# STM32WBA55 register map
File version: 1.0
CPU: CM33 r0p1, little endian, MPU, FPU, 4 interrupt priority bits
Registers are 32-bit, read-write, reset 0x0 unless marked. A register's access mark holds for its fields unless they carry their own. Offsets are from the block's base; [hi:lo] are bit positions; {n}, {i} and the like mark numbered series.

## ADC4 — ADC register block
Base 0x46021000
Same registers: SEC_ADC4 0x56021000
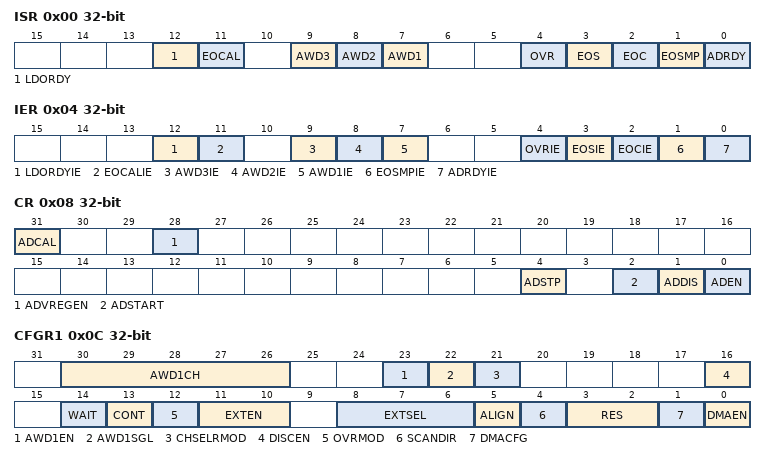
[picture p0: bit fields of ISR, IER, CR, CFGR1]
0x00 ISR — ADC interrupt and status register
  [12] LDORDY — LDO ready This bit is set by hardware. It indicates that the ADC internal LDO output is ready. It is cleared by software by writing 1 to it.
  [11] EOCAL — End of calibration flag This bit is set by hardware when calibration is complete. It is cleared by software writing 1 to it.
  [9] AWD3 — Analog watchdog 3 flag This bit is set by hardware when the converted voltage crosses the values programmed in ADC_AWD3TR and ADC_AWD3TR registers. It is cleared by software by writing 1 to it.
  [8] AWD2 — Analog watchdog 2 flag This bit is set by hardware when the converted voltage crosses the values programmed in ADC_AWD2TR and ADC_AWD2TR registers. It is cleared by software writing 1 to it.
  [7] AWD1 — Analog watchdog 1 flag This bit is set by hardware when the converted voltage crosses the values programmed in ADC_TR1 and ADC_HR1 registers. It is cleared by software by writing 1 to it.
  [4] OVR — ADC overrun This bit is set by hardware when an overrun occurs, meaning that a new conversion has complete while the EOC flag was already set. It is cleared by software writing 1 to it.
  [3] EOS — End of sequence flag This bit is set by hardware at the end of the conversion of a sequence of channels selected by the CHSEL bits. It is cleared by software writing 1 to it.
  [2] EOC — End of conversion flag This bit is set by hardware at the end of each conversion of a channel when a new data result is available in the ADC_DR register. It is cleared by software writing 1 to it or by reading the ADC_DR register.
  [1] EOSMP — End of sampling flag This bit is set by hardware during the conversion, at the end of the sampling phase.It is cleared by software by writing 1 to it.
  [0] ADRDY — ADC ready This bit is set by hardware after the ADC has been enabled (ADEN = 1) and when the ADC reaches a state where it is ready to accept conversion requests. It is cleared by software writing 1 to it.
0x04 IER — ADC interrupt enable register
  [12] LDORDYIE — LDO ready interrupt enable This bit is set and cleared by software. It is used to enable/disable the LDORDY interrupt. Note: The software is allowed to write this bit only when ADSTART bit is cleared to 0 by writing ADSTP to 1 (this ensure that no conversion is ongoing).
  [11] EOCALIE — End of calibration interrupt enable This bit is set and cleared by software to enable/disable the end of calibration interrupt. Note: The software is allowed to write this bit only when ADSTART bit is cleared to 0 by writing ADSTP to 1 (this ensures that no conversion is ongoing).
  [9] AWD3IE — Analog watchdog 3 interrupt enable This bit is set and cleared by software to enable/disable the analog watchdog interrupt. Note: The Software is allowed to write this bit only when ADSTART bit is cleared to 0 by writing ADSTP to 1 (this ensures that no conversion is ongoing).
  [8] AWD2IE — Analog watchdog 2 interrupt enable This bit is set and cleared by software to enable/disable the analog watchdog interrupt. Note: The Software is allowed to write this bit only when ADSTART bit is cleared to 0 by writing ADSTP to 1 (this ensures that no conversion is ongoing).
  [7] AWD1IE — Analog watchdog 1 interrupt enable This bit is set and cleared by software to enable/disable the analog watchdog interrupt. Note: The Software is allowed to write this bit only when ADSTART bit is cleared to 0 by writing ADSTP to 1 (this ensures that no conversion is ongoing).
  [4] OVRIE — Overrun interrupt enable This bit is set and cleared by software to enable/disable the overrun interrupt. Note: The software is allowed to write this bit only when ADSTART bit is cleared to 0 by writing ADSTP to 1 (this ensures that no conversion is ongoing).
  [3] EOSIE — End of conversion sequence interrupt enable This bit is set and cleared by software to enable/disable the end of sequence of conversions interrupt. Note: The software is allowed to write this bit only when ADSTART bit is cleared to 0 by writing ADSTP to 1 (this ensures that no conversion is ongoing).
  [2] EOCIE — End of conversion interrupt enable This bit is set and cleared by software to enable/disable the end of conversion interrupt. Note: The software is allowed to write this bit only when ADSTART bit is cleared to 0 by writing ADSTP to 1 (this ensures that no conversion is ongoing).
  [1] EOSMPIE — End of sampling flag interrupt enable This bit is set and cleared by software to enable/disable the end of the sampling phase interrupt. Note: The software is allowed to write this bit only when ADSTART bit is cleared to 0 by writing ADSTP to 1 (this ensures that no conversion is ongoing).
  [0] ADRDYIE — ADC ready interrupt enable This bit is set and cleared by software to enable/disable the ADC Ready interrupt. Note: The software is allowed to write this bit only when ADSTART bit is cleared to 0 by writing ADSTP to 1 (this ensures that no conversion is ongoing).
0x08 CR — ADC control register
  [31] ADCAL — ADC calibration This bit is set by software to start the calibration of the ADC. It is cleared by hardware after calibration is complete. Note: The software is allowed to set ADCAL only when the ADC is disabled (ADCAL = 0, ADSTART = 0, ADSTP = 0, ADDIS = 0, AUTOFF = 0, and ADEN = 0). Note: The software is allowed to update the calibration factor by writing ADC_CALFACT only when ADEN is set to 1 and ADSTART is cleared to 0 by writing ADSTP to 1 (ADC enabled and no conversion is ongoing).
  [28] ADVREGEN — ADC voltage regulator enable This bit is set by software, to enable the ADC internal voltage regulator. The voltage regulator output is available after tsubADCVREG_SETUP/sub. It is cleared by software to disable the voltage regulator. It can be cleared only if ADEN is et to 0. Note: The software is allowed to program this bit field only when the ADC is disabled (ADCAL = 0, ADSTART = 0, ADSTP = 0, ADDIS = 0 and ADEN = 0).
  [4] ADSTP — ADC stop conversion command This bit is set by software to stop and discard an ongoing conversion (ADSTP Command). It is cleared by hardware when the conversion is effectively discarded and the ADC is ready to accept a new start conversion command. Note: To clear the A/D converter state, ADSTP must be set to 1 even if ADSTART is cleared to 0 after the software trigger A/D conversion. It is recommended to set ADSTP to 1 whenever the configuration needs to be modified.
  [2] ADSTART — ADC start conversion command This bit is set by software to start ADC conversion. Depending on the EXTEN [1:0] configuration bits, a conversion either starts immediately (software trigger configuration) or once a hardware trigger event occurs (hardware trigger configuration). It is cleared by hardware: In single conversion mode (CONT = 0, DISCEN = 0), when software trigger is selected (EXTEN = 00): at the assertion of the end of Conversion Sequence (EOS) flag. In discontinuous conversion mode(CONT=0, DISCEN = 1), when the software trigger is selected (EXTEN = 00): at the assertion of the end of Conversion (EOC) flag. In all other cases: after the execution of the ADSTP command, at the same time as the ADSTP bit is cleared by hardware. Note: The software is allowed to set ADSTART only when ADEN = 1 and ADDIS = 0 (ADC is enabled and there is no pending request to disable the ADC).
  [1] ADDIS — ADC disable command This bit is set by software to disable the ADC (ADDIS command) and put it into power-down state (OFF state). It is cleared by hardware once the ADC is effectively disabled (ADEN is also cleared by hardware at this time). Note: Setting ADDIS to 1 is only effective when ADEN = 1 and ADSTART = 0 (which ensures that no conversion is ongoing)
  [0] ADEN — ADC enable command This bit is set by software to enable the ADC. The ADC is effectively ready to operate once the ADRDY flag has been set. It is cleared by hardware when the ADC is disabled, after the execution of the ADDIS command. Note: The software is allowed to set ADEN only when all bits of ADC_CR registers are 0 (ADCAL = 0, ADSTP = 0, ADSTART = 0, ADDIS = 0 and ADEN = 0)
0x0C CFGR1 — ADC configuration register 1
  [30:26] AWD1CH — Analog watchdog channel selection These bits are set and cleared by software. They select the input channel to be guarded by the analog watchdog. ..... Others: Reserved The channel selected by the AWDCH[4:0] bits must be also set into the CHSELR register. Note: The software is allowed to write this bit only when ADSTART bit is cleared to 0 by writing ADSTP to 1 (this ensures that no conversion is ongoing).
  [23] AWD1EN — Analog watchdog enable This bit is set and cleared by software. Note: The software is allowed to write this bit only when ADSTART bit is cleared to 0 by writing ADSTP to 1 (this ensures that no conversion is ongoing).
  [22] AWD1SGL — Enable the watchdog on a single channel or on all channels This bit is set and cleared by software to enable the analog watchdog on the channel identified by the AWDCH[4:0] bits or on all the channels Note: The software is allowed to write this bit only when ADSTART bit is cleared to 0 by writing ADSTP to 1 (this ensures that no conversion is ongoing).
  [21] CHSELRMOD — Mode selection of the ADC_CHSELR register This bit is set and cleared by software to control the ADC_CHSELR feature: Note: The software is allowed to write this bit only when ADSTART bit is cleared to 0 by writing ADSTP to 1 (this ensures that no conversion is ongoing).
  [16] DISCEN — Discontinuous mode This bit is set and cleared by software to enable/disable discontinuous mode. Note: It is not possible to have both discontinuous mode and continuous mode enabled: it is forbidden to set both bits DISCEN = 1 and CONT = 1. Note: The software is allowed to write this bit only when ADSTART bit is cleared to 0 by writing ADSTP to 1 (this ensures that no conversion is ongoing).
  [14] WAIT — Wait conversion mode This bit is set and cleared by software to enable/disable wait conversion mode.sup./sup Note: The software is allowed to write this bit only when ADSTART bit is cleared to 0 by writing ADSTP to 1 (this ensures that no conversion is ongoing).
  [13] CONT — Single / continuous conversion mode This bit is set and cleared by software. If it is set, conversion takes place continuously until it is cleared. Note: It is not possible to have both discontinuous mode and continuous mode enabled: it is forbidden to set both bits DISCEN = 1 and CONT = 1. Note: The software is allowed to write this bit only when ADSTART bit is cleared to 0 by writing ADSTP to 1 (this ensures that no conversion is ongoing).
  [12] OVRMOD — Overrun management mode This bit is set and cleared by software and configure the way data overruns are managed. Note: The software is allowed to write this bit only when ADSTART bit is cleared to 0 by writing ADSTP to 1 (this ensures that no conversion is ongoing).
  [11:10] EXTEN — External trigger enable and polarity selection These bits are set and cleared by software to select the external trigger polarity and enable the trigger. Note: The software is allowed to write this bit only when ADSTART bit is cleared to 0 by writing ADSTP to 1 (this ensures that no conversion is ongoing).
  [8:6] EXTSEL — External trigger selection These bits select the external event used to trigger the start of conversion (refer to table ADC interconnection in Section 20.4.2: ADC pins and internal signals for details): Note: The software is allowed to write this bit only when ADSTART bit is cleared to 0 by writing ADSTP to 1 (this ensures that no conversion is ongoing).
  [5] ALIGN — Data alignment This bit is set and cleared by software to select right or left alignment. Refer to Figure 78: Data alignment and resolution (oversampling disabled: OVSE = 0) on page 631 Note: The software is allowed to write this bit only when ADSTART bit is cleared to 0 by writing ADSTP to 1 (this ensures that no conversion is ongoing).
  [4] SCANDIR — Scan sequence direction This bit is set and cleared by software to select the direction in which the channels is scanned in the sequence. It is effective only if CHSELRMOD bit is cleared to 0. Note: The software is allowed to write this bit only when ADSTART bit is cleared to 0 by writing ADSTP to 1 (this ensures that no conversion is ongoing).
  [3:2] RES — Data resolution These bits are written by software to select the resolution of the conversion. Note: The software is allowed to write these bits only when ADSTART bit is cleared to 0 by writing ADSTP to 1 (this ensures that no conversion is ongoing).
  [1] DMACFG — Direct memory access configuration This bit is set and cleared by software to select between two DMA modes of operation and is effective only when DMAEN = 1. For more details, refer to Section : Managing converted data using the DMA on page 632 Note: The software is allowed to write this bit only when ADSTART bit is cleared to 0 by writing ADSTP to 1 (this ensures that no conversion is ongoing).
  [0] DMAEN — Direct memory access enable This bit is set and cleared by software to enable the generation of DMA requests. This allows the automatic management of the converted data by the DMA controller. For more details, refer to Section : Managing converted data using the DMA on page 632. Note: The software is allowed to write this bit only when ADSTART bit is cleared to 0 by writing ADSTP to 1 (this ensures that no conversion is ongoing).
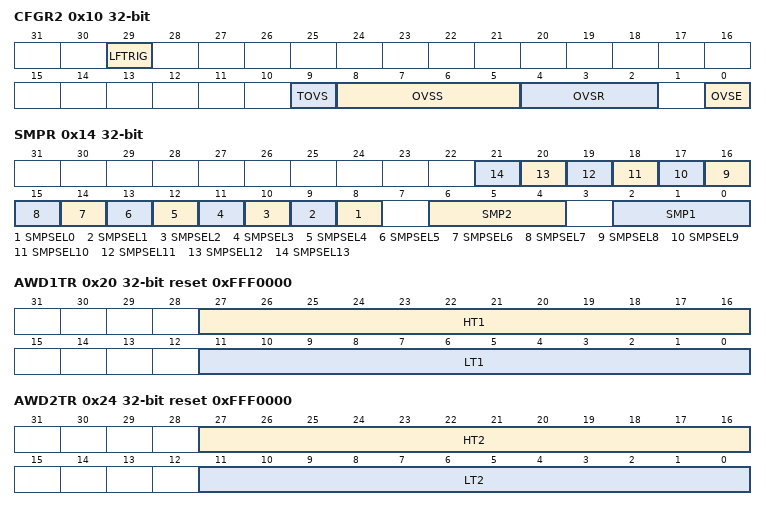
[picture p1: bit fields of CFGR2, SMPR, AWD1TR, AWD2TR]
0x10 CFGR2 — ADC configuration register 2
  [29] LFTRIG — Low frequency trigger mode enable This bit must be set by software. Note: The software is allowed to write this bit only when ADSTART bit is cleared to 0 by writing ADSTP to 1 (this ensures that no conversion is ongoing).
  [9] TOVS — Triggered Oversampling This bit is set and cleared by software. Note: The software is allowed to write this bit only when ADSTART is cleared to 0 by writing ADSTP to 1 (which ensures that no conversion is ongoing).
  [8:5] OVSS — Oversampling shift This bit is set and cleared by software. Others: Reserved Note: The software is allowed to write this bit only when ADSTART is cleared to 0 by writing ADSTP to 1(which ensures that no conversion is ongoing).
  [4:2] OVSR — Oversampling ratio This bit filed defines the number of oversampling ratio. Note: The software is allowed to write this bit only when ADSTART is cleared to 0 by writing ADSTP to 1 (which ensures that no conversion is ongoing).
  [0] OVSE — Oversampler Enable This bit is set and cleared by software. Note: Software is allowed to write this bit only when ADSTART is cleared to 0 by writing ADSTP to 1 (which ensures that no conversion is ongoing).
0x14 SMPR — ADC sampling time register
  [n+8] SMPSEL{n} (n=0..13) — Channel-x sampling time selection These bits are written by software to define which sampling time is used. Note: The software is allowed to write this bit only when ADSTART is cleared to 0 by writing ADSTP to 1 (which ensures that no conversion is ongoing).
  [6:4] SMP2 — Sampling time selection 2 These bits are written by software to select the sampling time that applies to all channels. Note: The software is allowed to write this bit only when ADSTART is cleared to 0 by writing ADSTP to 1 (which ensures that no conversion is ongoing).
  [2:0] SMP1 — Sampling time selection 1 These bits are written by software to select the sampling time that applies to all channels. Note: The software is allowed to write this bit only when ADSTART is cleared to 0 by writing ADSTP to 1 (which ensures that no conversion is ongoing).
0x20 AWD1TR reset 0xFFF0000 — ADC watchdog threshold register
  [27:16] HT1 — Analog watchdog 1 higher threshold These bits are written by software to define the higher threshold for the analog watchdog. Refer to Section 20.4.25: Analog window watchdog on page 638.
  [11:0] LT1 — Analog watchdog 1 lower threshold These bits are written by software to define the lower threshold for the analog watchdog. Refer to Section 20.4.25: Analog window watchdog on page 638.
0x24 AWD2TR reset 0xFFF0000 — ADC watchdog threshold register
  [27:16] HT2 — Analog watchdog 2 higher threshold These bits are written by software to define the higher threshold for the analog watchdog. Refer to Section 20.4.25: Analog window watchdog on page 638.
  [11:0] LT2 — Analog watchdog 2 lower threshold These bits are written by software to define the lower threshold for the analog watchdog. Refer to Section 20.4.25: Analog window watchdog on page 638.
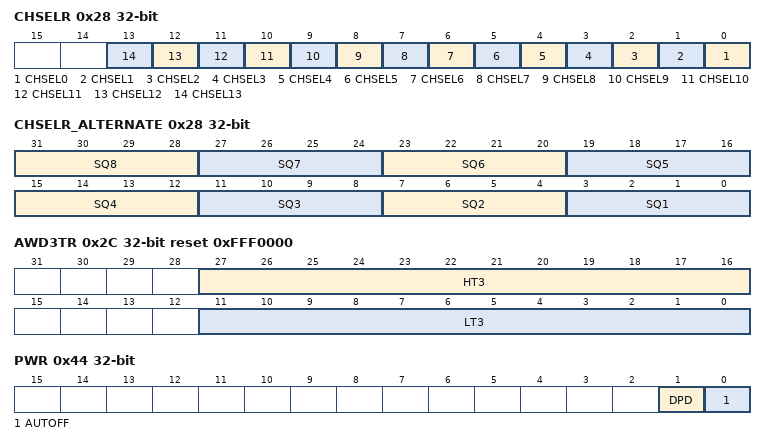
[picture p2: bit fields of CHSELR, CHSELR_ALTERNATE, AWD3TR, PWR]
0x28 CHSELR — ADC channel selection register [alternate]
  [n] CHSEL{n} (n=0..13) — Channel x selection These bits are written by software and define which channels are part of the sequence of channels to be converted. Note: The software is allowed to write this bit only when ADSTART is cleared to 0 by writing ADSTP to 1 (which ensures that no conversion is ongoing).
0x28 CHSELR_ALTERNATE (alternate view of CHSELR) — ADC channel selection register [alternate]
  [31:28] SQ8 — 8th conversion of the sequence These bits are programmed by software with the channel number assigned to the 8th conversion of the sequence. 0b1111 indicates the end of the sequence. When 0b1111 (end of sequence) is programmed to the lower sequence channels, these bits are ignored. ... Note: The software is allowed to write this bit only when ADSTART is cleared to 0 by writing ADSTP to 1 (which ensures that no conversion is ongoing).
  [27:24] SQ7 — 7th conversion of the sequence These bits are programmed by software with the channel number assigned to the 7th conversion of the sequence. 0b1111 indicates end of the sequence. When 0b1111 (end of sequence) is programmed to the lower sequence channels, these bits are ignored. Refer to SQ8[3:0] for a definition of channel selection. Note: The software is allowed to write this bit only when ADSTART is cleared to 0 by writing ADSTP to 1 (which ensures that no conversion is ongoing).
  [23:20] SQ6 — 6th conversion of the sequence These bits are programmed by software with the channel number assigned to the 6th conversion of the sequence. 0b1111 indicates end of the sequence. When 0b1111 (end of sequence) is programmed to the lower sequence channels, these bits are ignored. Refer to SQ8[3:0] for a definition of channel selection. Note: The software is allowed to write this bit only when ADSTART is cleared to 0 by writing ADSTP to 1 (which ensures that no conversion is ongoing).
  [19:16] SQ5 — 5th conversion of the sequence These bits are programmed by software with the channel number assigned to the 5th conversion of the sequence. 0b1111 indicates end of the sequence. When 0b1111 (end of sequence) is programmed to the lower sequence channels, these bits are ignored. Refer to SQ8[3:0] for a definition of channel selection. Note: The software is allowed to write this bit only when ADSTART is cleared to 0 by writing ADSTP to 1 (which ensures that no conversion is ongoing).
  [15:12] SQ4 — 4th conversion of the sequence These bits are programmed by software with the channel number assigned to the 4th conversion of the sequence. 0b1111 indicates end of the sequence. When 0b1111 (end of sequence) is programmed to the lower sequence channels, these bits are ignored. Refer to SQ8[3:0] for a definition of channel selection. Note: The software is allowed to write this bit only when ADSTART is cleared to 0 by writing ADSTP to 1(which ensures that no conversion is ongoing).
  [11:8] SQ3 — 3rd conversion of the sequence These bits are programmed by software with the channel number assigned to the 3rd conversion of the sequence. 0b1111 indicates end of the sequence. When 0b1111 (end of sequence) is programmed to the lower sequence channels, these bits are ignored. Refer to SQ8[3:0] for a definition of channel selection. Note: The software is allowed to write this bit only when ADSTART is cleared to 0 by writing ADSTP to 1 (which ensures that no conversion is ongoing).
  [7:4] SQ2 — 2nd conversion of the sequence These bits are programmed by software with the channel number assigned to the 2nd conversion of the sequence. 0b1111 indicates end of the sequence. When 0b1111 (end of sequence) is programmed to the lower sequence channels, these bits are ignored. Refer to SQ8[3:0] for a definition of channel selection. Note: The software is allowed to write this bit only when ADSTART is cleared to 0 by writing ADSTP to 1 (which ensures that no conversion is ongoing).
  [3:0] SQ1 — 1st conversion of the sequence These bits are programmed by software with the channel number assigned to the 1st conversion of the sequence. 0b1111 indicates end of the sequence. When 0b1111 (end of sequence) is programmed to the lower sequence channels, these bits are ignored. Refer to SQ8[3:0] for a definition of channel selection. Note: The software is allowed to write this bit only when ADSTART is cleared to 0 by writing ADSTP to 1 (which ensures that no conversion is ongoing).
0x2C AWD3TR reset 0xFFF0000 — ADC watchdog threshold register
  [27:16] HT3 — Analog watchdog 3 higher threshold These bits are written by software to define the higher threshold for the analog watchdog. Refer to Section 20.4.25: Analog window watchdog on page 638.
  [11:0] LT3 — Analog watchdog 3lower threshold These bits are written by software to define the lower threshold for the analog watchdog. Refer to Section 20.4.25: Analog window watchdog on page 638.
0x40 DR ro — ADC data register
  [15:0] DATA — Converted data These bits are read-only. They contain the conversion result from the last converted channel. The data are left- or right-aligned as shown in Figure 78: Data alignment and resolution (oversampling disabled: OVSE = 0) on page 631. Just after a calibration is complete, DATA[6:0] contains the calibration factor.
0x44 PWR — ADC data register
  [1] DPD — Deep-power-down mode bit This bit is set and cleared by software. It is used to enable/disable Deep-power-down mode in Autonomous mode when the ADC is not used. Note: The software is allowed to write this bit only when ADEN bit is cleared to 0 (this ensures that no conversion is ongoing). Note: Setting DPD in Auto-off mode automatically disables the LDO.
  [0] AUTOFF — Auto-off mode bit This bit is set and cleared by software. it is used to enable/disable the Auto-off mode. Note: The software is allowed to write this bit only when ADEN bit is cleared to 0 (this ensures that no conversion is ongoing).
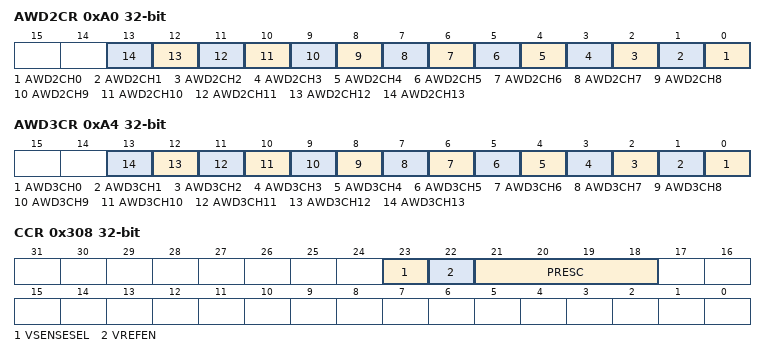
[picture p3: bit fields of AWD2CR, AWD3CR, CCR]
0xA0 AWD2CR — ADC Analog Watchdog 2 Configuration register
  [n] AWD2CH{n} (n=0..13) — Analog watchdog channel selection These bits are set and cleared by software. They enable and select the input channels to be guarded by analog watchdog 2 (AWD2). Note: The channels selected through ADC_AWD2CR must be also configured into the ADC_CHSELR registers. Refer to SQ8[3:0] for a definition of channel selection. The software is allowed to write this bit only when ADSTART is cleared to 0 by writing ADSTP to 1 (which ensures that no conversion is ongoing).
0xA4 AWD3CR — ADC Analog Watchdog 3 Configuration register
  [n] AWD3CH{n} (n=0..13) — Analog watchdog channel selection These bits are set and cleared by software. They enable and select the input channels to be guarded by analog watchdog 3 (AWD3). Note: The channels selected through ADC_AWD3CR must be also configured into the ADC_CHSELR registers. Refer to SQ8[3:0] for a definition of channel selection. The software is allowed to write this bit only when ADSTART is cleared to 0 by writing ADSTP to 1 (which ensures that no conversion is ongoing).
0xC4 CALFACT — ADC Calibration factor
  [6:0] CALFACT — Calibration factor These bits are written by hardware or by software. Once a calibration is complete, they are updated by hardware with the calibration factors. Software can write these bits with a new calibration factor. If the new calibration factor is different from the current one stored into the analog ADC, it is then applied once a new calibration is launched. Just after a calibration is complete, DATA[6:0] contains the calibration factor. Note: Software can write these bits only when ADEN = 1 (ADC is enabled and no calibration is ongoing and no conversion is ongoing).
0x308 CCR — ADC common configuration register
  [23] VSENSESEL — Temperature sensor selection This bit is set and cleared by software to enable/disable the temperature sensor. Note: Software is allowed to write this bit only when ADSTART is cleared to 0 by writing ADSTP to 1 (which ensures that no conversion is ongoing).
  [22] VREFEN — VsubREFINT/sub enable This bit is set and cleared by software to enable/disable the VsubREFINT/sub buffer. Note: Software is allowed to write this bit only when ADSTART is cleared to 0 by writing ADSTP to 1 (which ensures that no conversion is ongoing).
  [21:18] PRESC — ADC prescaler Set and cleared by software to select the frequency of the clock to the ADC. Other: Reserved Note: Software is allowed to write these bits only when the ADC is disabled (ADCAL = 0, ADSTART = 0, ADSTP = 0, ADDIS = 0 and ADEN = 0).
